# LKS32MC03x register map
Vendor: Linko Ltd.; Series: LKS32MC03x; File version: 1.0
CPU: CM0 r1p0, little endian, MPU, no FPU, 3 interrupt priority bits
Registers are 32-bit, read-write, reset 0x0 unless marked. A register's access mark holds for its fields unless they carry their own. Offsets are from the block's base; [hi:lo] are bit positions; {n}, {i} and the like mark numbered series.

## GPIO0 — GPIO0 registers
Base 0x40010800
0x00 PIE — GPIO0 input enable
  [15:0] PIE — GPIO0[n] input enable
0x04 POE — GPIO0 output enable
  [15:0] POE — GPIO0[n] output enable
0x08 PDI — GPIO0 input data
  [15:0] PDI — GPIO0[n] input data
0x0C PDO — GPIO0 output data
  [15:0] PDO — GPIO0[n] output data
0x10 PUE — GPIO0 pull-up enable
  [15:0] PUE — GPIO0[n] pull-up enable
0x18 PODE — GPIO0 open drain enable
  [15:0] PODE — GPIO0[n] open drain enable
0x1C PFLT — GPIO0 filter enable
  [15:0] PFLT — GPIO0[n] filter enable
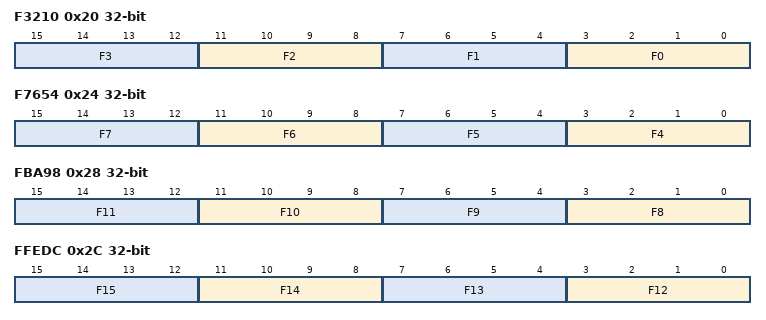
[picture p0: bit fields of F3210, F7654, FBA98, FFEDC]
0x20 F3210 — GPIO0[3:0] function selection
  [4n+3:4n] F{n} (n=0..3) — GPIO0[{n}] function selection
0x24 F7654 — GPIO0[7:4] function selection
  [4n-13:4n-16] F{n} (n=4..7) — GPIO0[{n}] function selection
0x28 FBA98 — GPIO0[11:8] function selection
  [4n-29:4n-32] F{n} (n=8..11) — GPIO0[{n}] function selection
0x2C FFEDC — GPIO0[15:12] function selection
  [4n-45:4n-48] F{n} (n=12..15) — GPIO0[{n-12}] function selection
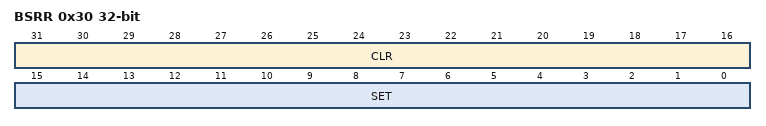
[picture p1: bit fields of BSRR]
0x30 BSRR wo — GPIO0 bit set reset reg
  [31:16] CLR — GPIO0[n] write 1 to clear
  [15:0] SET — GPIO0[n] write 1 to set
0x34 BRR wo — GPIO0 bit reset reg
  [15:0] CLR — GPIO0[n] write 1 to clear

## GPIO1 — GPIO1 registers
Base 0x40010840
Registers as GPIO0 (with GPIO0 read as GPIO1).

## EXTI — EXTI registers
Base 0x40010880
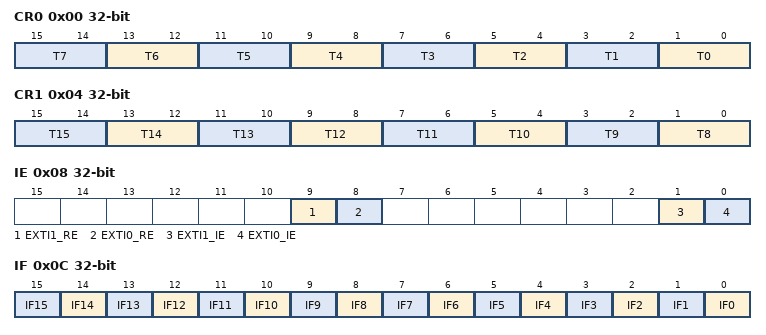
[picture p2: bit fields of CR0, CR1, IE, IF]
0x00 CR0 — GPIO0[7:0] external interrupt trigger type
  [2n+1:2n] T{n} (n=0..7) — GPIO0[{n}] external interrupt trigger type
0x04 CR1 — GPIO0[15:8] external interrupt trigger type
  [2n-15:2n-16] T{n} (n=8..15) — GPIO0[{n}] external interrupt trigger type
0x08 IE — GPIO interrupt enable
  [9] EXTI1_RE — GPIO1 DMA enable
  [8] EXTI0_RE — GPIO0 DMA enable
  [1] EXTI1_IE — GPIO1 interrupt enable
  [0] EXTI0_IE — GPIO0 interrupt enable
0x0C IF — GPIO interrupt flag
  [n] IF{n} (n=0..15) — GPIO0[{n}] interrupt flag
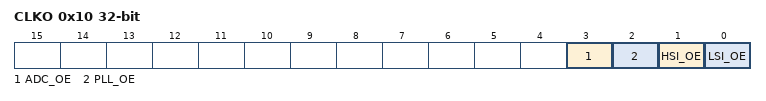
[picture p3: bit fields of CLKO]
0x10 CLKO — GPIO output clock selection
  [3] ADC_OE — ADC output enable
  [2] PLL_OE — PLL output enable
  [1] HSI_OE — HSI output enable
  [0] LSI_OE — LSI output enable

## UART — UART registers
Base 0x40010900
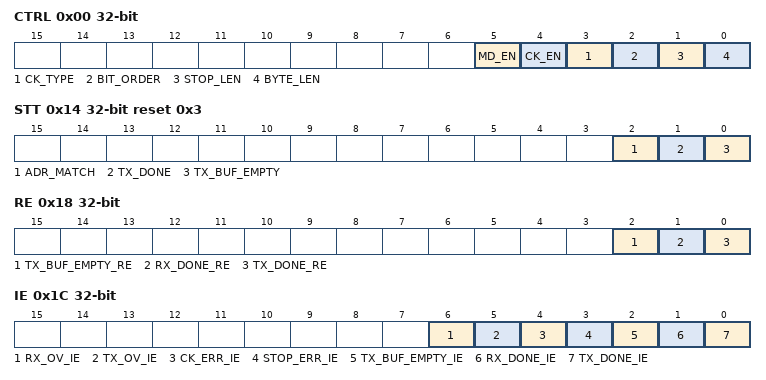
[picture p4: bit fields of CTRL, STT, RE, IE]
0x00 CTRL — UART control
  [5] MD_EN — Multi-drop mode enable
    0=DISABLED (Multi-drop mode disabled); 1=ENABLED (Multi-drop mode enabled)
  [4] CK_EN — Odd-Even Check enable
    0=DISABLED (Odd-Even check disabled); 1=ENABLED (Odd-Even check enabled)
  [3] CK_TYPE — Odd or Even Check
    0=EVEN (Even check); 1=ODD (Odd check)
  [2] BIT_ORDER — LSB or MSB first
    0=LSB; 1=MSB
  [1] STOP_LEN — Stop bit length
    0=1B (1bit stop bit); 1=2B (2bit stop bit)
  [0] BYTE_LEN — Data length
    0=8B (8bit data); 1=9B (9bit data)
0x04 DIVH — UART Baudrate higher byte
  [7:0] DIVH — Baudrate higher byte
0x08 DIVL — UART Baudrate lower byte
  [7:0] DIVL — Baudrate lower byte
0x0C BUFF — UART read/write buffer
  [8:0] DATA — Write by Tx data, read as Rx data
0x10 ADR — UART match address as RS485
  [7:0] ADR — UART address as a slave
0x14 STT ro reset 0x3 — UART status
  [2] ADR_MATCH — Address matched in multi-drop mode
  [1] TX_DONE — Transmission fnished
  [0] TX_BUF_EMPTY — TX Buffer empty
0x18 RE — UART DMA request enable
  [2] TX_BUF_EMPTY_RE — TX Buffer empty DMA request enable
  [1] RX_DONE_RE — Byte received DMA request enable
  [0] TX_DONE_RE — Byte transmission finished DMA request flag
0x1C IE — UART interrupt enable
  [6] RX_OV_IE — RX overflow interrupt enable
  [5] TX_OV_IE — TX overflow interrupt enable
  [4] CK_ERR_IE — Check error interrupt enable
  [3] STOP_ERR_IE — Stop bit error interrupt enable
  [2] TX_BUF_EMPTY_IE — TX Buffer empty interrupt enable
  [1] RX_DONE_IE — Byte received interrupt enable
  [0] TX_DONE_IE — Byte transmission finished interrupt flag
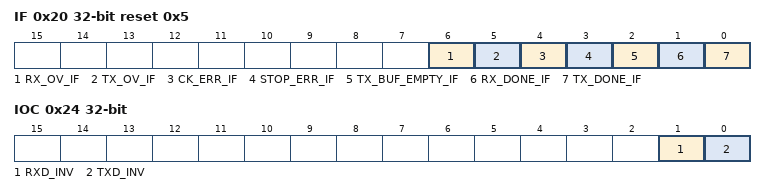
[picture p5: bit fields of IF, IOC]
0x20 IF reset 0x5 — UART interrupt flag
  [6] RX_OV_IF — RX overflow interrupt flag
  [5] TX_OV_IF — TX overflow interrupt flag
  [4] CK_ERR_IF — Check error interrupt flag
  [3] STOP_ERR_IF — Stop bit error interrupt flag
  [2] TX_BUF_EMPTY_IF — TX Buffer empty interrupt flag
  [1] RX_DONE_IF — Byte received interrupt flag
  [0] TX_DONE_IF — Byte transmission finished interrupt flag
0x24 IOC — UART IO Control
  [1] RXD_INV — RXD inverted then input
  [0] TXD_INV — TXD inverted then output
